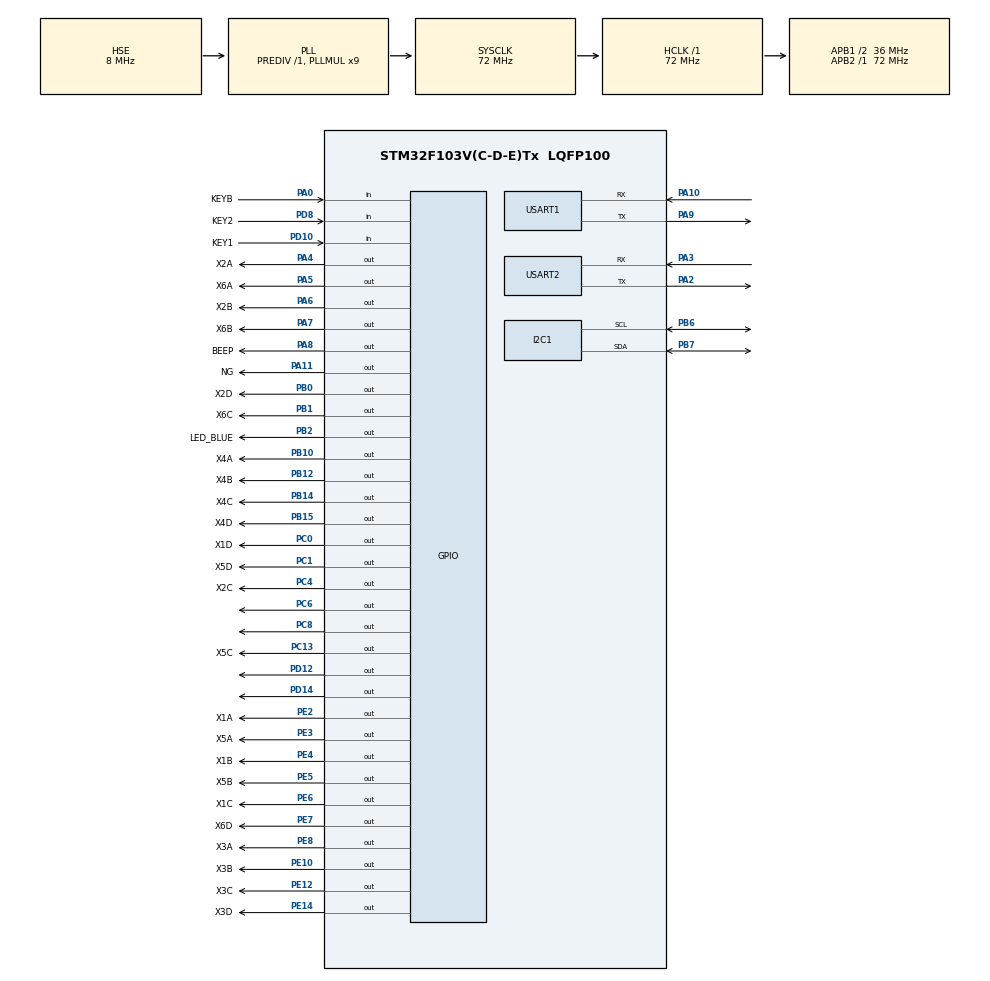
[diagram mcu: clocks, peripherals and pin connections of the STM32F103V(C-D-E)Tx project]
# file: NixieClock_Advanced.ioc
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FREERTOS.INCLUDE_uxTaskGetStackHighWaterMark=1
FREERTOS.Tasks01=Nixie_display,0,128,AppNixie_display,As weak,NULL,Dynamic,NULL,NULL;ReadRTC,1,128,AppReadRTC,As weak,NULL,Dynamic,NULL,NULL;EntireHourBBjia,-1,128,AppEntireHourBBjiao,As weak,NULL,Dynamic,NULL,NULL
FREERTOS.configTIMER_TASK_PRIORITY=4
FREERTOS.configTIMER_TASK_STACK_DEPTH=128
FREERTOS.configUSE_TIMERS=0
Mcu.Family=STM32F1
Mcu.Name=STM32F103V(C-D-E)Tx
Mcu.Package=LQFP100
NVIC.PriorityGroup=NVIC_PRIORITYGROUP_4
NVIC.TIM6_IRQn=true\:0\:0\:true\:false\:true\:false\:true\:true\:true
NVIC.TIM7_IRQn=true\:5\:0\:false\:false\:true\:true\:true\:true\:true
NVIC.TimeBase=TIM6_IRQn
NVIC.TimeBaseIP=TIM6
OSC_IN.Mode=HSE-External-Oscillator
OSC_IN.Signal=RCC_OSC_IN
OSC_OUT.Mode=HSE-External-Oscillator
OSC_OUT.Signal=RCC_OSC_OUT
PA0-WKUP.GPIO_Label=KEYB
PA0-WKUP.Signal=GPIO_Input
PA10.Mode=Asynchronous
PA10.Signal=USART1_RX
PA11.GPIO_Label=NG
PA11.Signal=GPIO_Output
PA13.Mode=Serial_Wire
PA13.Signal=SYS_JTMS-SWDIO
PA14.Mode=Serial_Wire
PA14.Signal=SYS_JTCK-SWCLK
PA2.Mode=Asynchronous
PA2.Signal=USART2_TX
PA3.Mode=Asynchronous
PA3.Signal=USART2_RX
PA4.GPIO_Label=X2A
PA4.GPIO_PuPd=GPIO_PULLUP
PA4.PinState=GPIO_PIN_SET
PA4.Signal=GPIO_Output
PA5.GPIO_Label=X6A
PA5.GPIO_PuPd=GPIO_PULLUP
PA5.PinState=GPIO_PIN_SET
PA5.Signal=GPIO_Output
PA6.GPIO_Label=X2B
PA6.GPIO_PuPd=GPIO_PULLUP
PA6.PinState=GPIO_PIN_SET
PA6.Signal=GPIO_Output
PA7.GPIO_Label=X6B
PA7.GPIO_PuPd=GPIO_PULLUP
PA7.PinState=GPIO_PIN_SET
PA7.Signal=GPIO_Output
PA8.GPIO_Label=BEEP
PA8.Signal=GPIO_Output
PA9.Mode=Asynchronous
PA9.Signal=USART1_TX
PB0.GPIO_Label=X2D
PB0.GPIO_PuPd=GPIO_PULLUP
PB0.PinState=GPIO_PIN_SET
PB0.Signal=GPIO_Output
PB1.GPIO_Label=X6C
PB1.GPIO_PuPd=GPIO_PULLUP
PB1.PinState=GPIO_PIN_SET
PB1.Signal=GPIO_Output
PB10.GPIO_Label=X4A
PB10.GPIO_PuPd=GPIO_PULLUP
PB10.PinState=GPIO_PIN_SET
PB10.Signal=GPIO_Output
PB12.GPIO_Label=X4B
PB12.GPIO_PuPd=GPIO_PULLUP
PB12.PinState=GPIO_PIN_SET
PB12.Signal=GPIO_Output
PB14.GPIO_Label=X4C
PB14.GPIO_PuPd=GPIO_PULLUP
PB14.PinState=GPIO_PIN_SET
PB14.Signal=GPIO_Output
PB15.GPIO_Label=X4D
PB15.GPIO_PuPd=GPIO_PULLUP
PB15.PinState=GPIO_PIN_SET
PB15.Signal=GPIO_Output
PB2.GPIO_Label=LED_BLUE
PB2.Signal=GPIO_Output
PB6.Mode=I2C
PB6.Signal=I2C1_SCL
PB7.Mode=I2C
PB7.Signal=I2C1_SDA
PC0.GPIO_Label=X1D
PC0.GPIO_PuPd=GPIO_NOPULL
PC0.PinState=GPIO_PIN_SET
PC0.Signal=GPIO_Output
PC1.GPIO_Label=X5D
PC1.GPIO_PuPd=GPIO_PULLUP
PC1.PinState=GPIO_PIN_SET
PC1.Signal=GPIO_Output
PC13-TAMPER-RTC.GPIO_Label=X5C
PC13-TAMPER-RTC.GPIO_PuPd=GPIO_PULLUP
PC13-TAMPER-RTC.PinState=GPIO_PIN_SET
PC13-TAMPER-RTC.Signal=GPIO_Output
PC4.GPIO_Label=X2C
PC4.GPIO_PuPd=GPIO_PULLUP
PC4.PinState=GPIO_PIN_SET
PC4.Signal=GPIO_Output
PC6.Signal=GPIO_Output
PC8.Signal=GPIO_Output
PD10.GPIO_Label=KEY1
PD10.Signal=GPIO_Input
PD12.Signal=GPIO_Output
PD14.Signal=GPIO_Output
PD8.GPIO_Label=KEY2
PD8.Signal=GPIO_Input
PE10.GPIO_Label=X3B
PE10.GPIO_PuPd=GPIO_PULLUP
PE10.PinState=GPIO_PIN_SET
PE10.Signal=GPIO_Output
PE12.GPIO_Label=X3C
PE12.GPIO_PuPd=GPIO_PULLUP
PE12.PinState=GPIO_PIN_SET
PE12.Signal=GPIO_Output
PE14.GPIO_Label=X3D
PE14.GPIO_PuPd=GPIO_PULLUP
PE14.PinState=GPIO_PIN_SET
PE14.Signal=GPIO_Output
PE2.GPIO_Label=X1A
PE2.PinState=GPIO_PIN_SET
PE2.Signal=GPIO_Output
PE3.GPIO_Label=X5A
PE3.GPIO_PuPd=GPIO_PULLUP
PE3.PinState=GPIO_PIN_SET
PE3.Signal=GPIO_Output
PE4.GPIO_Label=X1B
PE4.GPIO_PuPd=GPIO_NOPULL
PE4.PinState=GPIO_PIN_SET
PE4.Signal=GPIO_Output
PE5.GPIO_Label=X5B
PE5.GPIO_PuPd=GPIO_PULLUP
PE5.PinState=GPIO_PIN_SET
PE5.Signal=GPIO_Output
PE6.GPIO_Label=X1C
PE6.GPIO_PuPd=GPIO_NOPULL
PE6.PinState=GPIO_PIN_SET
PE6.Signal=GPIO_Output
PE7.GPIO_Label=X6D
PE7.GPIO_PuPd=GPIO_PULLUP
PE7.PinState=GPIO_PIN_SET
PE7.Signal=GPIO_Output
PE8.GPIO_Label=X3A
PE8.GPIO_PuPd=GPIO_PULLUP
PE8.PinState=GPIO_PIN_SET
PE8.Signal=GPIO_Output
ProjectManager.HeapSize=0x200
ProjectManager.StackSize=0x400
ProjectManager.TargetToolchain=MDK-ARM V5.32
RCC.AHBFreq_Value=72000000
RCC.APB1CLKDivider=RCC_HCLK_DIV2
RCC.APB1Freq_Value=36000000
RCC.APB1TimFreq_Value=72000000
RCC.APB2Freq_Value=72000000
RCC.APB2TimFreq_Value=72000000
RCC.HCLKFreq_Value=72000000
RCC.PLLMUL=RCC_PLL_MUL9
RCC.PLLSourceVirtual=RCC_PLLSOURCE_HSE
RCC.SYSCLKFreq_VALUE=72000000
RCC.SYSCLKSource=RCC_SYSCLKSOURCE_PLLCLK
RCC.USBFreq_Value=72000000
TIM7.Period=9999
TIM7.Prescaler=7199
USART1.VirtualMode=VM_ASYNC
USART2.VirtualMode=VM_ASYNC
VP_FREERTOS_VS_CMSIS_V1.Mode=CMSIS_V1
VP_SYS_VS_tim6.Mode=TIM6
VP_TIM7_VS_ClockSourceINT.Mode=Enable_Timer
board=custom

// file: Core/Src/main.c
/* USER CODE BEGIN Header */
/**
  ******************************************************************************
  * @file           : main.c
  * @brief          : Main program body
  ******************************************************************************
  * @attention
  *
  * Copyright (c) 2024 STMicroelectronics.
  * All rights reserved.
  *
  * This software is licensed under terms that can be found in the LICENSE file
  * in the root directory of this software component.
  * If no LICENSE file comes with this software, it is provided AS-IS.
  *
  ******************************************************************************
  */
/* USER CODE END Header */
#include "main.h"
#include "cmsis_os.h"
#include "i2c.h"
#include "tim.h"
#include "usart.h"
#include "gpio.h"

/* USER CODE BEGIN PV */
extern osTimerId BlinkerTimerHandle;
/* USER CODE END PV */

void SystemClock_Config(void);
void MX_FREERTOS_Init(void);

int main(void)
{

  /* MCU Configuration--------------------------------------------------------*/

  /* Reset of all peripherals, Initializes the Flash interface and the Systick. */
  HAL_Init();

  /* Configure the system clock */
  SystemClock_Config();

  /* Initialize all configured peripherals */
  MX_GPIO_Init();
  MX_I2C1_Init();
  MX_USART1_UART_Init();
  MX_USART2_UART_Init();
  MX_TIM7_Init();
  /* USER CODE BEGIN 2 */
    OLED_Initial();
    DS1307_Init(&hi2c1);
    HAL_TIM_Base_Start_IT(&htim7);
  /* USER CODE END 2 */

  /* Call init function for freertos objects (in cmsis_os2.c) */
  MX_FREERTOS_Init();

  /* Start scheduler */
  osKernelStart();

  /* We should never get here as control is now taken by the scheduler */

  /* Infinite loop */
    while (1) {

    }
}

void SystemClock_Config(void)
{
  RCC_OscInitTypeDef RCC_OscInitStruct = {0};
  RCC_ClkInitTypeDef RCC_ClkInitStruct = {0};

  /** Initializes the RCC Oscillators according to the specified parameters
  * in the RCC_OscInitTypeDef structure.
  */
  RCC_OscInitStruct.OscillatorType = RCC_OSCILLATORTYPE_HSE;
  RCC_OscInitStruct.HSEState = RCC_HSE_ON;
  RCC_OscInitStruct.HSEPredivValue = RCC_HSE_PREDIV_DIV1;
  RCC_OscInitStruct.HSIState = RCC_HSI_ON;
  RCC_OscInitStruct.PLL.PLLState = RCC_PLL_ON;
  RCC_OscInitStruct.PLL.PLLSource = RCC_PLLSOURCE_HSE;
  RCC_OscInitStruct.PLL.PLLMUL = RCC_PLL_MUL9;
  if (HAL_RCC_OscConfig(&RCC_OscInitStruct) != HAL_OK)
  {
    Error_Handler();
  }

  /** Initializes the CPU, AHB and APB buses clocks
  */
  RCC_ClkInitStruct.ClockType = RCC_CLOCKTYPE_HCLK|RCC_CLOCKTYPE_SYSCLK
                              |RCC_CLOCKTYPE_PCLK1|RCC_CLOCKTYPE_PCLK2;
  RCC_ClkInitStruct.SYSCLKSource = RCC_SYSCLKSOURCE_PLLCLK;
  RCC_ClkInitStruct.AHBCLKDivider = RCC_SYSCLK_DIV1;
  RCC_ClkInitStruct.APB1CLKDivider = RCC_HCLK_DIV2;
  RCC_ClkInitStruct.APB2CLKDivider = RCC_HCLK_DIV1;

  if (HAL_RCC_ClockConfig(&RCC_ClkInitStruct, FLASH_LATENCY_2) != HAL_OK)
  {
    Error_Handler();
  }
}

void HAL_TIM_PeriodElapsedCallback(TIM_HandleTypeDef *htim)
{
  if (htim->Instance == TIM6) {
    HAL_IncTick();
  }
  /* USER CODE BEGIN Callback 1 */
    if (htim->Instance == TIM7) {
        HAL_GPIO_TogglePin(LED_BLUE_GPIO_Port, LED_BLUE_Pin);
    }

  /* USER CODE END Callback 1 */
}

void Error_Handler(void)
{
    __disable_irq();
    while (1) {
    }
}

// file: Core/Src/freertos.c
/* USER CODE BEGIN Header */
/**
  ******************************************************************************
  * File Name          : freertos.c
  * Description        : Code for freertos applications
  ******************************************************************************
  * @attention
  *
  * Copyright (c) 2024 STMicroelectronics.
  * All rights reserved.
  *
  * This software is licensed under terms that can be found in the LICENSE file
  * in the root directory of this software component.
  * If no LICENSE file comes with this software, it is provided AS-IS.
  *
  ******************************************************************************
  */
/* USER CODE END Header */

#include "FreeRTOS.h"
#include "task.h"
#include "main.h"
#include "cmsis_os.h"

osThreadId Nixie_displayHandle;
osThreadId ReadRTCHandle;
osThreadId EntireHourBBjiaHandle;

void AppNixie_display(void const * argument);
void AppReadRTC(void const * argument);
void AppEntireHourBBjiao(void const * argument);

void MX_FREERTOS_Init(void); /* (MISRA C 2004 rule 8.1) */

/* GetIdleTaskMemory prototype (linked to static allocation support) */
void vApplicationGetIdleTaskMemory( StaticTask_t **ppxIdleTaskTCBBuffer, StackType_t **ppxIdleTaskStackBuffer, uint32_t *pulIdleTaskStackSize );

/* USER CODE BEGIN GET_IDLE_TASK_MEMORY */
static StaticTask_t xIdleTaskTCBBuffer;
static StackType_t xIdleStack[configMINIMAL_STACK_SIZE];

void vApplicationGetIdleTaskMemory( StaticTask_t **ppxIdleTaskTCBBuffer, StackType_t **ppxIdleTaskStackBuffer, uint32_t *pulIdleTaskStackSize )
{
  *ppxIdleTaskTCBBuffer = &xIdleTaskTCBBuffer;
  *ppxIdleTaskStackBuffer = &xIdleStack[0];
  *pulIdleTaskStackSize = configMINIMAL_STACK_SIZE;
  /* place for user code */
}
/* USER CODE END GET_IDLE_TASK_MEMORY */

void MX_FREERTOS_Init(void) {

  /* Create the thread(s) */
  /* definition and creation of Nixie_display */
  osThreadDef(Nixie_display, AppNixie_display, osPriorityNormal, 0, 128);
  Nixie_displayHandle = osThreadCreate(osThread(Nixie_display), NULL);

  /* definition and creation of ReadRTC */
  osThreadDef(ReadRTC, AppReadRTC, osPriorityAboveNormal, 0, 128);
  ReadRTCHandle = osThreadCreate(osThread(ReadRTC), NULL);

  /* definition and creation of EntireHourBBjia */
  osThreadDef(EntireHourBBjia, AppEntireHourBBjiao, osPriorityBelowNormal, 0, 128);
  EntireHourBBjiaHandle = osThreadCreate(osThread(EntireHourBBjia), NULL);

}

__weak void AppNixie_display(void const * argument)
{
  for(;;)
  {
    osDelay(1);
  }
}

__weak void AppReadRTC(void const * argument)
{
  for(;;)
  {
    osDelay(1);
  }
}

__weak void AppEntireHourBBjiao(void const * argument)
{
  for(;;)
  {
    osDelay(1);
  }
}
